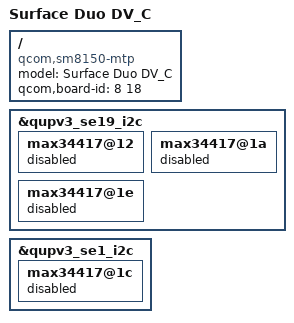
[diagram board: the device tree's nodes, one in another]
/*
 * Copyright (c) 2020 Microsoft Corporation
 *
 * This program is free software; you can redistribute it and/or modify it
 * under the terms of the GNU General Public License version 2 as published by
 * the Free Software Foundation.
 */

/dts-v1/;
/plugin/;

#include <dt-bindings/clock/qcom,gcc-sm8150.h>
#include <dt-bindings/clock/qcom,camcc-sm8150.h>
#include <dt-bindings/clock/qcom,rpmh.h>
#include <dt-bindings/interrupt-controller/arm-gic.h>

#include "surface-duo.dtsi"

/ {
	model = "Surface Duo DV_C";
	compatible = "qcom,sm8150-mtp", "qcom,sm8150", "qcom,mtp";
	qcom,board-id = <8 18>;
};

&qupv3_se19_i2c { // Disable R2 Power Monitors for EV2.1

        max34417@12 {
                status = "disabled";
        };

        max34417@1a {
                status = "disabled";
        };

        max34417@1e {
                status = "disabled";
        };
};

&qupv3_se1_i2c { // Disable C3 Power Monitors for EV2.1

        max34417@1c {
                status = "disabled";
        };
};
